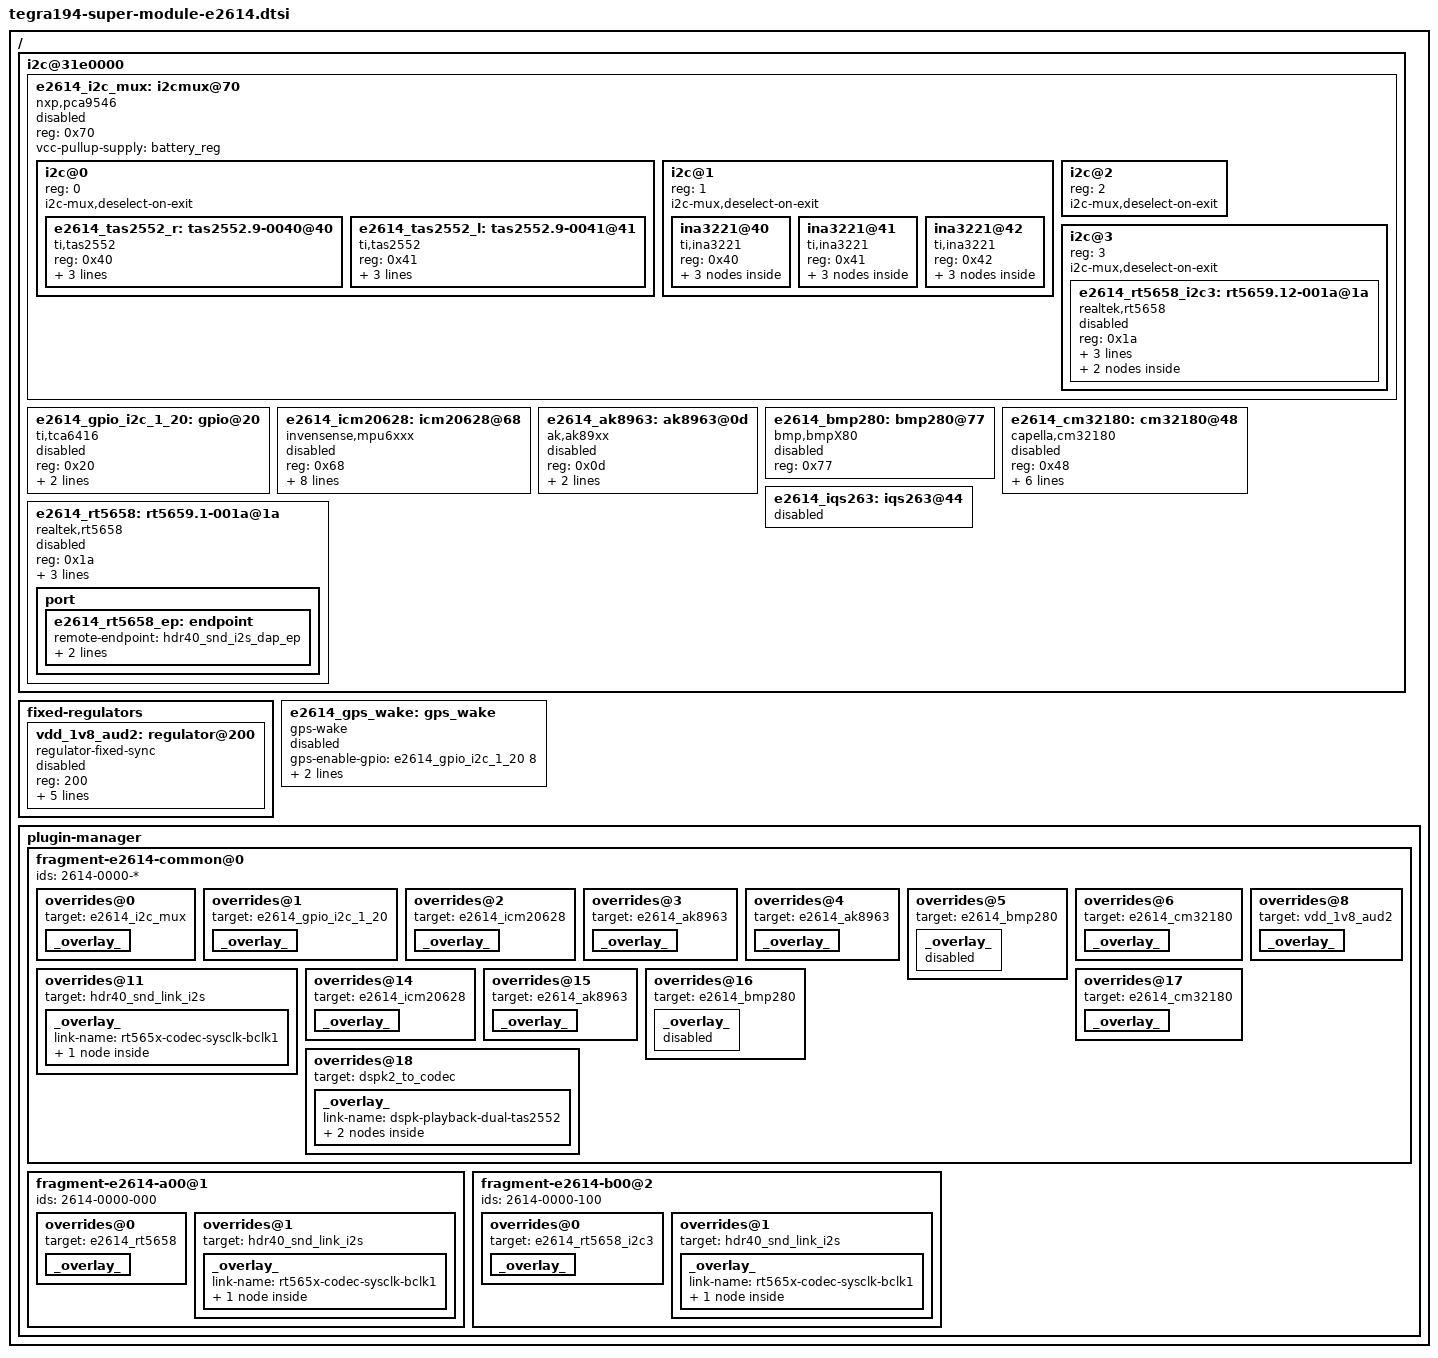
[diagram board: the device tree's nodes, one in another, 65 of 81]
// SPDX-License-Identifier: GPL-2.0-only
/*
 * tegra194-super-module-e2614.dtsi: E2600 DTSI file.
 *
 * Copyright (c) 2018-2022, NVIDIA CORPORATION & AFFILIATES. All rights reserved.
 *
 */

/ {
	i2c@31e0000 {
		e2614_i2c_mux: i2cmux@70 {
			compatible = "nxp,pca9546";
			reg = <0x70>;
			#address-cells = <1>;
			#size-cells = <0>;
			vcc-pullup-supply = <&battery_reg>;
			status = "disabled";
			i2c@0 {
				reg = <0>;
				i2c-mux,deselect-on-exit;
				#address-cells = <1>;
				#size-cells = <0>;
				e2614_tas2552_r:tas2552.9-0040@40 {
					compatible = "ti,tas2552";
					reg = <0x40>;
					vbat-supply = <&battery_reg>;
					avdd-supply = <&vdd_1v8_aud2>;
					tas2552,pdm_edge_select = <0>;
					#sound-dai-cells = <1>;
				};
				e2614_tas2552_l:tas2552.9-0041@41 {
                                        compatible = "ti,tas2552";
                                        reg = <0x41>;
                                        vbat-supply = <&battery_reg>;
                                        avdd-supply = <&vdd_1v8_aud2>;
					tas2552,pdm_edge_select = <1>;
					#sound-dai-cells = <1>;
                                };
			};
			i2c@1 {
				reg = <1>;
				i2c-mux,deselect-on-exit;
				#address-cells = <1>;
				#size-cells = <0>;
				ina3221@40 {
					compatible = "ti,ina3221";
					reg = <0x40>;
					#address-cells = <1>;
					#size-cells = <0>;
					channel@0 {
						reg = <0x0>;
						label = "VDD_5V";
						shunt-resistor-micro-ohms = <10000>;
					};
					channel@1 {
						reg = <0x1>;
						label = "VDD_3V3";
						shunt-resistor-micro-ohms = <10000>;
					};
					channel@2 {
						reg = <0x2>;
						label = "VDD_1V8";
						shunt-resistor-micro-ohms = <1000>;
					};
				};
				ina3221@41 {
					compatible = "ti,ina3221";
					reg = <0x41>;
					#address-cells = <1>;
					#size-cells = <0>;
					channel@0 {
						reg = <0x0>;
						label = "VDD_5V_AUD";
						shunt-resistor-micro-ohms = <1000>;
					};
					channel@1 {
						reg = <0x1>;
						label = "VDD_3V3_AUD";
						shunt-resistor-micro-ohms = <10000>;
					};
					channel@2 {
						reg = <0x2>;
						label = "VDD_1V8_AUD";
						shunt-resistor-micro-ohms = <10000>;
					};
				};
				ina3221@42 {
					compatible = "ti,ina3221";
					reg = <0x42>;
					#address-cells = <1>;
					#size-cells = <0>;
					channel@0 {
						reg = <0x0>;
						label = "VDD_3V3_GPS";
						shunt-resistor-micro-ohms = <10000>;
					};
					channel@1 {
						reg = <0x1>;
						label = "VDD_3V3_NFC";
						shunt-resistor-micro-ohms = <10000>;
					};
					channel@2 {
						reg = <0x2>;
						label = "VDD_3V3_GYRO";
						shunt-resistor-micro-ohms = <10000>;
					};
				};
			};
			i2c@2 {
				reg = <2>;
				i2c-mux,deselect-on-exit;
				#address-cells = <1>;
				#size-cells = <0>;
			};
			i2c@3 {
				reg = <3>;
				i2c-mux,deselect-on-exit;
				#address-cells = <1>;
				#size-cells = <0>;
				e2614_rt5658_i2c3: rt5659.12-001a@1a {
					compatible = "realtek,rt5658";
					reg = <0x1a>;
					status = "disabled";

					/* refer include/sound/rt5659.h for the values to be used */
					realtek,jd-src = <1>; /* RT5659_JD3 */
					realtek,dmic1-data-pin = <2>; /* RT5659_DMIC1_DATA_GPIO5 */
					#sound-dai-cells = <1>;

					sound-name-prefix = "H40-RT";

					port {
						e2614_rt5658_i2c3_ep: endpoint {
							remote-endpoint = <&hdr40_snd_i2s_dap_ep>;
							mclk-fs = <256>;
							link-name = "rt565x-codec-sysclk-bclk1";
						};
					};
				};
			};
		};

		e2614_gpio_i2c_1_20: gpio@20 {
			compatible = "ti,tca6416";
			reg = <0x20>;
			gpio-controller;
			#gpio-cells = <2>;
			vcc-supply = <&battery_reg>;
			status = "disabled";
		};

                e2614_icm20628: icm20628@68 {
                        compatible = "invensense,mpu6xxx";
                        reg = <0x68>;
                        interrupt-parent = <&tegra_aon_gpio>;
                        interrupts = <TEGRA194_AON_GPIO(AA, 2) 0x01>;
                        accelerometer_matrix	= [01 00 00 00 01 00 00 00 01];
                        gyroscope_matrix	= [01 00 00 00 01 00 00 00 01];
			geomagnetic_rotation_vector_disable = <1>;
			gyroscope_uncalibrated_disable = <1>;
			quaternion_disable = <1>;
			status = "disabled";
                };

                e2614_ak8963: ak8963@0d {
                        compatible = "ak,ak89xx";
                        reg = <0x0d>;
                        magnetic_field_matrix	= [01 00 00 00 01 00 00 00 01];
			status = "disabled";
                };

                e2614_bmp280: bmp280@77 {
                        compatible = "bmp,bmpX80";
                        reg = <0x77>;
			status = "disabled";
                };

                e2614_cm32180: cm32180@48 {
                        compatible = "capella,cm32180";
                        reg = <0x48>;
                        gpio_irq = <&tegra_aon_gpio TEGRA194_AON_GPIO(AA, 1) GPIO_ACTIVE_LOW>;
                        light_uncalibrated_lo = <1>;
                        light_calibrated_lo = <150>;
                        light_uncalibrated_hi = <95000>;
                        light_calibrated_hi = <1750000>;
			status = "disabled";
                };

                e2614_iqs263: iqs263@44 {
			status = "disabled";
                };

		e2614_rt5658: rt5659.1-001a@1a {
			compatible = "realtek,rt5658";
			reg = <0x1a>;
			status = "disabled";

			/* refer include/sound/rt5659.h for the values to be used */
			realtek,jd-src = <1>; /* RT5659_JD3 */
			realtek,dmic1-data-pin = <2>; /* RT5659_DMIC1_DATA_GPIO5 */
			#sound-dai-cells = <1>;

			sound-name-prefix = "H40-RT";

			port {
				e2614_rt5658_ep: endpoint {
					remote-endpoint = <&hdr40_snd_i2s_dap_ep>;
					mclk-fs = <256>;
					link-name = "rt565x-codec-sysclk-bclk1";
				};
			};
		};
	};

	fixed-regulators {
		vdd_1v8_aud2: regulator@200 {
			compatible = "regulator-fixed-sync", "regulator-fixed";
			reg = <200>;
			regulator-name = "vdd-1v8-aud2";
			regulator-min-microvolt = <1800000>;
			regulator-max-microvolt = <1800000>;
			gpio = <&e2614_gpio_i2c_1_20 11 1>; /*DSPK EN*/
			enable-active-high;
			status = "disabled";
		};
	};

	e2614_gps_wake: gps_wake {
		compatible = "gps-wake";
		gps-enable-gpio = <&e2614_gpio_i2c_1_20 8 0>;
		gps-wakeup-gpio = <&tegra_main_gpio TEGRA194_AON_GPIO(AA, 0) 0>;
		status = "disabled";
	};

	plugin-manager {
		fragment-e2614-common@0 {
			ids = "2614-0000-*";
			overrides@0 {
				target = <&e2614_i2c_mux>;
				_overlay_ {
					status = "okay";
				};
			};
			overrides@1 {
				target = <&e2614_gpio_i2c_1_20>;
				_overlay_ {
					status = "okay";
				};
			};
			overrides@2 {
				target = <&e2614_icm20628>;
				_overlay_ {
					status = "okay";
				};
			};
			overrides@3 {
				target = <&e2614_ak8963>;
				_overlay_ {
					status = "okay";
				};
			};
			overrides@4 {
				target = <&e2614_ak8963>;
				_overlay_ {
					status = "okay";
				};
			};
			overrides@5 {
				target = <&e2614_bmp280>;
				_overlay_ {
					status = "disabled";
				};
			};
			overrides@6 {
				target = <&e2614_cm32180>;
				_overlay_ {
					status = "okay";
				};
			};
			overrides@8 {
				target = <&vdd_1v8_aud2>;
				_overlay_ {
					status = "okay";
				};
			};

			overrides@11 {
				target = <&hdr40_snd_link_i2s>;
				_overlay_ {
					link-name = "rt565x-codec-sysclk-bclk1";
					codec {
						sound-dai = <&e2614_rt5658 0>;
						prefix = "H40-RT";
					};
				};
			};
			overrides@14 {
                                target = <&e2614_icm20628>;
                                _overlay_ {
                                        status = "okay";
                                };
                        };
			overrides@15 {
                                target = <&e2614_ak8963>;
                                _overlay_ {
                                        status = "okay";
                                };
                        };
			overrides@16 {
                                target = <&e2614_bmp280>;
                                _overlay_ {
                                        status = "disabled";
                                };
                        };
			overrides@17 {
                                target = <&e2614_cm32180>;
                                _overlay_ {
                                        status = "okay";
                                };
                        };
			overrides@18 {
                                target = <&dspk2_to_codec>;
                                _overlay_ {
					link-name = "dspk-playback-dual-tas2552";

					codec {
						sound-dai = <&e2614_tas2552_r 0>;
						prefix = "H40-TAS-R";
					};

					codec@1 {
						sound-dai = <&e2614_tas2552_l 0>;
						prefix = "H40-TAS-L";
					};
				};
			};
		};

		fragment-e2614-a00@1 {
			ids = "2614-0000-000";
			overrides@0 {
				target = <&e2614_rt5658>;
				_overlay_ {
					status = "okay";
				};
			};
			overrides@1 {
				target = <&hdr40_snd_link_i2s>;
				_overlay_ {
					link-name = "rt565x-codec-sysclk-bclk1";
					codec {
						sound-dai = <&e2614_rt5658 0>;
						prefix = "H40-RT";
					};
				};
			};
		};

		fragment-e2614-b00@2 {
			ids = "2614-0000-100";
			overrides@0 {
				target = <&e2614_rt5658_i2c3>;
				_overlay_ {
					status = "okay";
				};
			};

			overrides@1 {
				target = <&hdr40_snd_link_i2s>;
				_overlay_ {
					link-name = "rt565x-codec-sysclk-bclk1";
					codec {
						sound-dai = <&e2614_rt5658_i2c3 0>;
						prefix = "H40-RT";
					};
				};
			};
		};
	};
};
